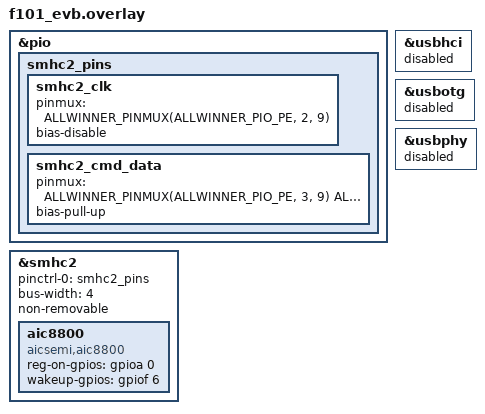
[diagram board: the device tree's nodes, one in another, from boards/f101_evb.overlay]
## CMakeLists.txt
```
# SPDX-License-Identifier: Apache-2.0

cmake_minimum_required(VERSION 3.20.0)
# the AIC8800 module is two directories up
list(APPEND ZEPHYR_EXTRA_MODULES ${CMAKE_CURRENT_SOURCE_DIR}/../..)

find_package(Zephyr REQUIRED HINTS $ENV{ZEPHYR_BASE})
project(wifi_scan)

target_sources(app PRIVATE src/main.c)
```

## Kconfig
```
# SPDX-License-Identifier: Apache-2.0

mainmenu "AIC8800 WiFi scan"

config SAMPLE_WIFI_SSID
	string "SSID to connect to after the scan (empty: scan only)"
	default ""

config SAMPLE_WIFI_PSK
	string "WPA2 passphrase"
	default ""

source "Kconfig.zephyr"
```

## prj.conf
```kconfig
CONFIG_AIC8800=y

# wpa_supplicant 的任务在 picolibc 下一启动就退出（控制口为 -1），连接不能工作，所以用最小 C 库
CONFIG_MINIMAL_LIBC=y

CONFIG_LOG=y
CONFIG_PRINTK=y
CONFIG_SHELL=n
CONFIG_MAIN_STACK_SIZE=8192
CONFIG_COMMON_LIBC_MALLOC_ARENA_SIZE=-1
CONFIG_HEAP_MEM_POOL_SIZE=262144
CONFIG_FPU=y
CONFIG_FPU_SHARING=y
CONFIG_SYSTEM_WORKQUEUE_STACK_SIZE=4096

CONFIG_NETWORKING=y
CONFIG_NET_IPV4=y
CONFIG_NET_IPV6=n
CONFIG_NET_UDP=y
CONFIG_NET_TCP=y
CONFIG_NET_DHCPV4=y
CONFIG_NET_MGMT=y
CONFIG_NET_MGMT_EVENT=y
CONFIG_NET_MGMT_EVENT_INFO=y
CONFIG_NET_L2_ETHERNET=y
CONFIG_WIFI=y
CONFIG_NET_L2_WIFI_MGMT=y

CONFIG_SDHC=y
CONFIG_GPIO=y
CONFIG_DISPLAY=n
CONFIG_G2D=n
CONFIG_USB_PHY_SUNXI=n
CONFIG_ADC=n
CONFIG_SPI=n
CONFIG_I2C=n
CONFIG_MIPI_DBI=n
CONFIG_WDT_SUNXI=n
CONFIG_VDEC=n

# keys of the handshakes need random numbers; this is a pseudo random source until the SoC
# random generator has a driver
CONFIG_TEST_RANDOM_GENERATOR=y
```

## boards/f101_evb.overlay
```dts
/*
 * AIC8800 module on the SD host controller 2 (SMHC2), pins PE0..PE5 mux 9, power
 * enable on PA0 and the wakeup line on PF6.
 *
 * Those pins are shared: PE2 is the switch of the USB host VBUS and PE0..PE4 are the pins
 * of I2S0, so neither of them can be used together with this overlay (the USB host is
 * switched off below). PF6 is also the card detect of the SD slot, it is only read here.
 */
&pio {
	smhc2_pins: smhc2_pins {
		smhc2_clk {
			pinmux = <ALLWINNER_PINMUX(ALLWINNER_PIO_PE, 2, 9)>;
			bias-disable;
		};
		smhc2_cmd_data {
			pinmux = <ALLWINNER_PINMUX(ALLWINNER_PIO_PE, 3, 9)
				  ALLWINNER_PINMUX(ALLWINNER_PIO_PE, 1, 9)
				  ALLWINNER_PINMUX(ALLWINNER_PIO_PE, 0, 9)
				  ALLWINNER_PINMUX(ALLWINNER_PIO_PE, 5, 9)
				  ALLWINNER_PINMUX(ALLWINNER_PIO_PE, 4, 9)>;
			bias-pull-up;
		};
	};
};

&usbhci {
	status = "disabled";
};

&usbotg {
	status = "disabled";
};

&usbphy {
	status = "disabled";
};

&smhc2 {
	pinctrl-0 = <&smhc2_pins>;
	pinctrl-names = "default";
	bus-width = <4>;
	non-removable;
	status = "okay";

	aic8800 {
		compatible = "aicsemi,aic8800";
		reg-on-gpios = <&gpioa 0 GPIO_ACTIVE_HIGH>;
		wakeup-gpios = <&gpiof 6 GPIO_ACTIVE_HIGH>;
	};
};
```

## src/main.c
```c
/*
 * Copyright (c) 2026 Yuzuki Tsuru
 * SPDX-License-Identifier: Apache-2.0
 */

/*
 * Scans for access points, prints them, and when an SSID is configured connects
 * to it with WPA2-PSK and waits for the address from DHCP.
 */

#include <string.h>
#include <zephyr/kernel.h>
#include <zephyr/net/net_if.h>
#include <zephyr/net/net_mgmt.h>
#include <zephyr/net/wifi_mgmt.h>
#include <zephyr/sys/printk.h>

#define EVENTS (NET_EVENT_WIFI_SCAN_RESULT | NET_EVENT_WIFI_SCAN_DONE | \
		NET_EVENT_WIFI_CONNECT_RESULT | NET_EVENT_WIFI_DISCONNECT_RESULT)

static struct net_mgmt_event_callback wifi_cb, ipv4_cb;
static K_SEM_DEFINE(scan_done, 0, 1);
static K_SEM_DEFINE(connected, 0, 1);
static K_SEM_DEFINE(got_ip, 0, 1);
static int found;

static void wifi_event(struct net_mgmt_event_callback *cb, uint64_t event, struct net_if *iface)
{
	switch (event) {
	case NET_EVENT_WIFI_SCAN_RESULT: {
		const struct wifi_scan_result *r = cb->info;

		printk("%2d  ch %3d  rssi %4d  %-12s  %.*s\n", ++found, r->channel, r->rssi,
		       r->security == WIFI_SECURITY_TYPE_NONE ? "open" :
		       r->security == WIFI_SECURITY_TYPE_PSK ? "WPA2-PSK" : "secured",
		       r->ssid_length, r->ssid);
		break;
	}
	case NET_EVENT_WIFI_SCAN_DONE:
		k_sem_give(&scan_done);
		break;
	case NET_EVENT_WIFI_CONNECT_RESULT: {
		const struct wifi_status *s = cb->info;

		printk("connect: %s (%d)\n", s->status == 0 ? "ok" : "failed", s->status);
		if (s->status == 0) {
			k_sem_give(&connected);
		}
		break;
	}
	case NET_EVENT_WIFI_DISCONNECT_RESULT:
		printk("disconnected\n");
		break;
	}
}

static void ipv4_event(struct net_mgmt_event_callback *cb, uint64_t event, struct net_if *iface)
{
	if (event == NET_EVENT_IPV4_ADDR_ADD) {
		char buf[NET_IPV4_ADDR_LEN];

		printk("address: %s\n",
		       net_addr_ntop(AF_INET, &iface->config.ip.ipv4->unicast[0].ipv4.address.in_addr,
				     buf, sizeof(buf)));
		k_sem_give(&got_ip);
	}
}

int main(void)
{
	struct net_if *iface = net_if_get_first_wifi();

	if (iface == NULL) {
		printk("no WiFi interface\n");
		return 0;
	}
	net_mgmt_init_event_callback(&wifi_cb, wifi_event, EVENTS);
	net_mgmt_add_event_callback(&wifi_cb);
	net_mgmt_init_event_callback(&ipv4_cb, ipv4_event, NET_EVENT_IPV4_ADDR_ADD);
	net_mgmt_add_event_callback(&ipv4_cb);

	printk("scanning\n");
	if (net_mgmt(NET_REQUEST_WIFI_SCAN, iface, NULL, 0) != 0) {
		printk("scan request failed\n");
		return 0;
	}
	k_sem_take(&scan_done, K_SECONDS(30));
	printk("%d access points\n", found);

	if (strlen(CONFIG_SAMPLE_WIFI_SSID) > 0) {
		struct wifi_connect_req_params p = {
			.ssid = CONFIG_SAMPLE_WIFI_SSID,
			.ssid_length = strlen(CONFIG_SAMPLE_WIFI_SSID),
			.psk = CONFIG_SAMPLE_WIFI_PSK,
			.psk_length = strlen(CONFIG_SAMPLE_WIFI_PSK),
			.security = strlen(CONFIG_SAMPLE_WIFI_PSK) ? WIFI_SECURITY_TYPE_PSK :
								     WIFI_SECURITY_TYPE_NONE,
			.channel = WIFI_CHANNEL_ANY,
			.band = WIFI_FREQ_BAND_UNKNOWN,
		};

		printk("connecting to %s\n", CONFIG_SAMPLE_WIFI_SSID);
		if (net_mgmt(NET_REQUEST_WIFI_CONNECT, iface, &p, sizeof(p)) != 0) {
			printk("connect request failed\n");
			return 0;
		}
		if (k_sem_take(&connected, K_SECONDS(30)) == 0 &&
		    k_sem_take(&got_ip, K_SECONDS(30)) != 0) {
			printk("no address from DHCP\n");
		}
	}

	return 0;
}
```
